# GD32F50x register map
File version: 1.0
CPU: CM33 r2p1, little endian, MPU, FPU, 4 interrupt priority bits
Registers are 32-bit, read-write, reset 0x0 unless marked. A register's access mark holds for its fields unless they carry their own. Offsets are from the block's base; [hi:lo] are bit positions; {n}, {i} and the like mark numbered series.

## AFIO — Alternate-function I/Os
Base 0x40010000
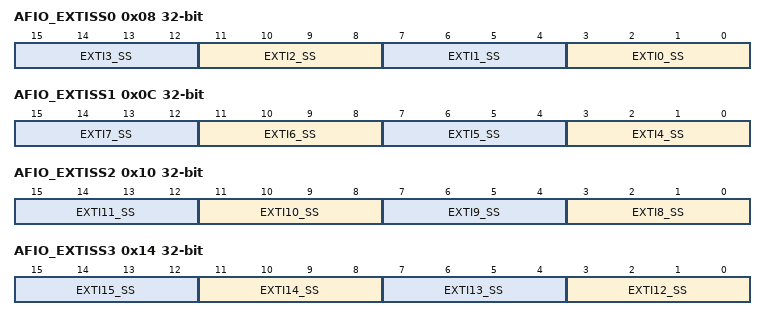
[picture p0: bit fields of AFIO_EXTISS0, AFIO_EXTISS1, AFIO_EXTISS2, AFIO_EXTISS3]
0x08 AFIO_EXTISS0 — EXTI sources selection register 0
  [4n+3:4n] EXTI{n}_SS (n=0..3) — EXTI {n} sources selection
0x0C AFIO_EXTISS1 — EXTI sources selection register 1
  [4n-13:4n-16] EXTI{n}_SS (n=4..7) — EXTI {n} sources selection
0x10 AFIO_EXTISS2 — EXTI sources selection register 2
  [4n-29:4n-32] EXTI{n}_SS (n=8..11) — EXTI {n} sources selection
0x14 AFIO_EXTISS3 — EXTI sources selection register 3
  [4n-45:4n-48] EXTI{n}_SS (n=12..15) — EXTI {n} sources selection

## BKP — Backup registers
Base 0x40006C00
{0x4+4i} DATA{i} (i=0..9) — Backup data register {i}
  [15:0] DATA — Backup data
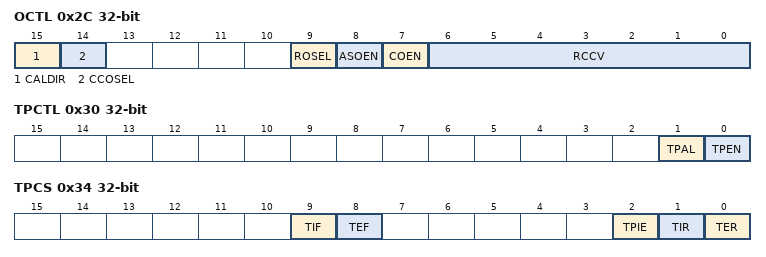
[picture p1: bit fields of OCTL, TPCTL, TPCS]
0x2C OCTL — RTC signal output control register
  [15] CALDIR — RTC clock calibration direction
  [14] CCOSEL — RTC clock output selection
  [9] ROSEL — RTC output selection
  [8] ASOEN — RTC alarm or second signal output enable
  [7] COEN — RTC clock calibration output enable
  [6:0] RCCV — RTC clock calibration value
0x30 TPCTL — Tamper pin control register
  [1] TPAL — TAMPER pin active level
  [0] TPEN — TAMPER detection enable
0x34 TPCS — Tamper control and status register
  [9] TIF — Tamper interrupt flag
  [8] TEF — Tamper event flag
  [2] TPIE — Tamper interrupt enable
  [1] TIR — Tamper interrupt reset
  [0] TER — Tamper event reset
{0x18+4i} DATA{i} (i=10..41) — Backup data register {i}
  [15:0] DATA — Backup data

## CAU — Cryptographic acceleration unit
Base 0x48021000
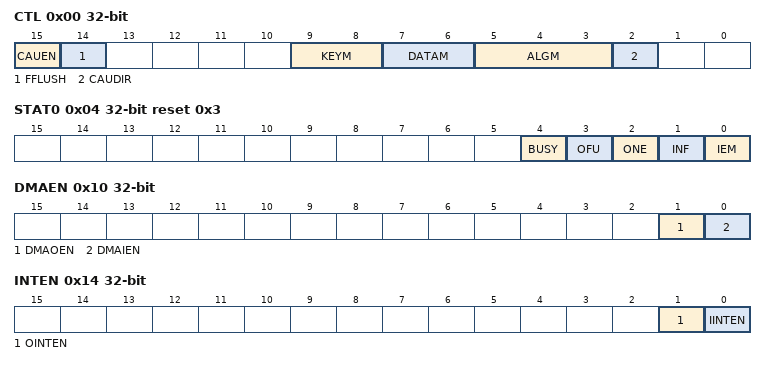
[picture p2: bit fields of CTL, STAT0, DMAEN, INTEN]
0x00 CTL access per field — CAU control register
  [15] CAUEN rw — Cryptographic module enable
  [14] FFLUSH wo — FIFO flush
  [9:8] KEYM rw — AES key size mode configuration
  [7:6] DATAM rw — Data swapping type mode configuration
  [5:3] ALGM rw — Encryption/decryption algorithm mode
  [2] CAUDIR rw — CAU direction
0x04 STAT0 ro reset 0x3 — CAU status register 0
  [4] BUSY — BUSY flag
  [3] OFU — OUT FIFO full flag
  [2] ONE — OUT FIFO not empty flag
  [1] INF — IN FIFO not full flag
  [0] IEM — IN FIFO empty flag
0x08 DI — CAU data input register
  [31:0] DI — Data input
0x0C DO ro — CAU data output register
  [31:0] DO — Data output
0x10 DMAEN — CAU DMA enable register
  [1] DMAOEN — Out FIFO DMA enable
  [0] DMAIEN — In FIFO DMA enable
0x14 INTEN — CAU interrupt enable register
  [1] OINTEN — Out FIFO interrupt enable
  [0] IINTEN — In FIFO interrupt enable
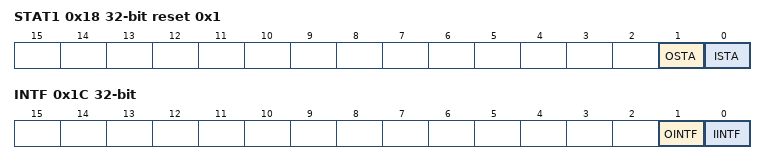
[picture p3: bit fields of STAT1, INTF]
0x18 STAT1 ro reset 0x1 — CAU interrupt status flag register 1
  [1] OSTA — Out FIFO interrupt flag
  [0] ISTA — In FIFO interrupt flag
0x1C INTF ro — CAU enable interrupt status flag register
  [1] OINTF — Out FIFO enabled interrupt flag
  [0] IINTF — In FIFO enabled interrupt flag
{0x20+8i} KEY{i}H wo (i=0..3) — CAU key register
  [31:0] KEY{i}H — Key for DES,TDES,AES
{0x24+8i} KEY{i}L wo (i=0..3) — CAU key register
  [31:0] KEY{i}L — Key for DES,TDES,AES

## CRC — cyclic redundancy check calculation unit
Base 0x40023000
0x00 DATA reset 0xFFFFFFFF
  [31:0] DATA — CRC calculation result bits
0x04 FDATA — Free data register
  [7:0] FDATA — Free Data Register bits
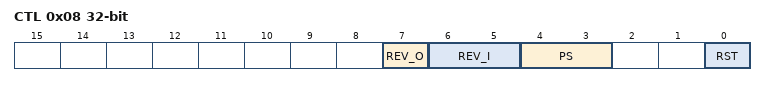
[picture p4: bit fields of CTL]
0x08 CTL — Control register
  [7] REV_O — Reverse output data value in bit order
  [6:5] REV_I — Reverse type for input data
  [4:3] PS — Size of polynomial
  [0] RST — reset bit
0x10 IDATA reset 0xFFFFFFFF — Initialization data register
  [31:0] IDATA — Configurable initial CRC data value
0x14 POLY reset 0x4C11DB7 — Polynomial register
  [31:0] POLY — User configurable polynomial value

## CTC — Clock trim controller
Base 0x4000C800
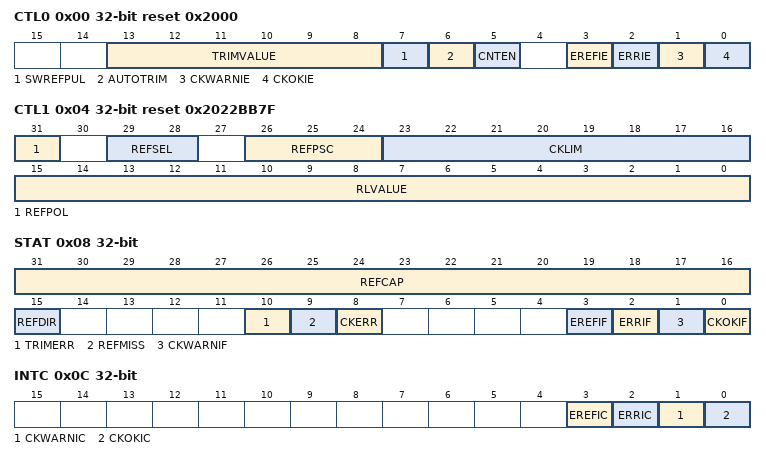
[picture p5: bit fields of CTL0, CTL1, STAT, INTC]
0x00 CTL0 reset 0x2000 — Control register 0
  [13:8] TRIMVALUE — IRC48M trim value
  [7] SWREFPUL — Software reference source sync pulse
  [6] AUTOTRIM — Hardware automatically trim mode
  [5] CNTEN — CTC counter enable
  [3] EREFIE — EREFIF interrupt enable
  [2] ERRIE — Error interrupt enable
  [1] CKWARNIE — Clock trim warning interrupt enable
  [0] CKOKIE — Clock trim ok interrupt enable
0x04 CTL1 reset 0x2022BB7F — Control register 1
  [31] REFPOL — Reference signal source polarity
  [29:28] REFSEL — Reference signal source selection
  [26:24] REFPSC — Reference signal source prescaler
  [23:16] CKLIM — Clock trim base limit value
  [15:0] RLVALUE — CTC counter reload value
0x08 STAT ro — Status register
  [31:16] REFCAP — CTC counter capture when reference sync pulse
  [15] REFDIR — CTC trim counter direction when reference sync pulse
  [10] TRIMERR — Trim value error bit
  [9] REFMISS — Reference sync pulse miss
  [8] CKERR — Clock trim error bit
  [3] EREFIF — Expect reference interrupt flag
  [2] ERRIF — Error interrupt flag
  [1] CKWARNIF — Clock trim warning interrupt flag
  [0] CKOKIF — Clock trim OK interrupt flag
0x0C INTC wo — Interrupt clear register
  [3] EREFIC — EREFIF interrupt clear bit
  [2] ERRIC — ERRIF interrupt clear bit
  [1] CKWARNIC — CKWARNIF interrupt clear bit
  [0] CKOKIC — CKOKIF interrupt clear bit
